AUTOSAR XML (schema 00051)
package /Components
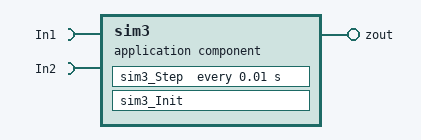
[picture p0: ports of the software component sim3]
  application sw component type sim3
    require port In1: nonqueued-receiver-com-spec{data-element=In1, init-value=0}, required-interface=In1
    require port In2: nonqueued-receiver-com-spec{data-element=In2, init-value=0}, required-interface=In2
    provide port zout: nonqueued-sender-com-spec{data-element=zout, init-value=0}, provided-interface=zout
    behavior sim3_IB: data-type-mapping=sim3DataTypeMappingsSet, handle-termination-and-restart=NO-SUPPORT
      constant-memorys:
        parameter data prototype kgain: category=VALUE, sw-calibration-access=READ-WRITE, type=uint32
      timing event Event_sim3_Step: start-on-event=sim3_Step, period=0.01
      runnable sim3_Init
      runnable sim3_Step
        data-read-access:
          access IN_In1_In1: accessed-variable=In1.In1
          access IN_In2_In2: accessed-variable=In2.In2
        data-write-access:
          access OUT_zout_zout: accessed-variable=zout.zout
